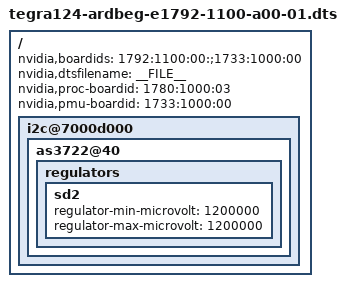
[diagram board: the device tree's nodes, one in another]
/dts-v1/;

#include "tegra124-ardbeg-e1780-1000-a03-common.dtsi"
#include "tegra124-platforms/tegra124-ardbeg-pmic-e1733-1000-a00.dtsi"
#include "tegra124-platforms/tegra124-ardbeg-fixed-e1733-1000-a00.dtsi"

/ {
	nvidia,boardids = "1792:1100:00:;1733:1000:00";
	nvidia,dtsfilename = __FILE__;
	nvidia,proc-boardid = "1780:1000:03";
	nvidia,pmu-boardid = "1733:1000:00";

	i2c@7000d000 {
		as3722@40 {
			regulators {
				sd2 {
					regulator-min-microvolt = <1200000>;
					regulator-max-microvolt = <1200000>;
				};
			};
		};
	};
};
